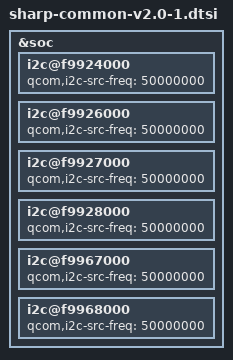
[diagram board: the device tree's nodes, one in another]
/* Copyright (c) 2012-2013, The Linux Foundation. All rights reserved.
 *
 * This program is free software; you can redistribute it and/or modify
 * it under the terms of the GNU General Public License version 2 and
 * only version 2 as published by the Free Software Foundation.
 *
 * This program is distributed in the hope that it will be useful,
 * but WITHOUT ANY WARRANTY; without even the implied warranty of
 * MERCHANTABILITY or FITNESS FOR A PARTICULAR PURPOSE.  See the
 * GNU General Public License for more details.
 */

&soc {
	/* I2C clock frequency overrides */
	i2c@f9924000 {
		qcom,i2c-src-freq = <50000000>;
	};
	i2c@f9926000 {
		qcom,i2c-src-freq = <50000000>;
	};
	i2c@f9927000 {
		qcom,i2c-src-freq = <50000000>;
	};
	i2c@f9928000 {
		qcom,i2c-src-freq = <50000000>;
	};
	i2c@f9967000 {
		qcom,i2c-src-freq = <50000000>;
	};
	i2c@f9968000 {
		qcom,i2c-src-freq = <50000000>;
	};
};
